# ATSAM4E16CB device description
Architecture: CORTEX-M4; Family: SAM4; Series: SAM4E
Registers are 32-bit, read-write, no defined reset value unless marked. A register's access mark holds for its fields unless they carry their own. Offsets are from the block's base; [hi:lo] are bit positions; {n}, {i} and the like mark numbered series.

## GPBR — General Purpose Backup Registers
Instances: GPBR 0x400E1890
{0x0+4i} SYS_GPBR{i} (i=0..19) — General Purpose Backup Register {i}
  [31:0] GPBR_VALUE — Value of GPBR x

## MATRIX — AHB Bus Matrix
Instances: MATRIX 0x400E0200
{0x0+4i} MATRIX_MCFG{i} (i=0..6) — Master Configuration Register {i}
  [2:0] ULBT — Undefined Length Burst Type
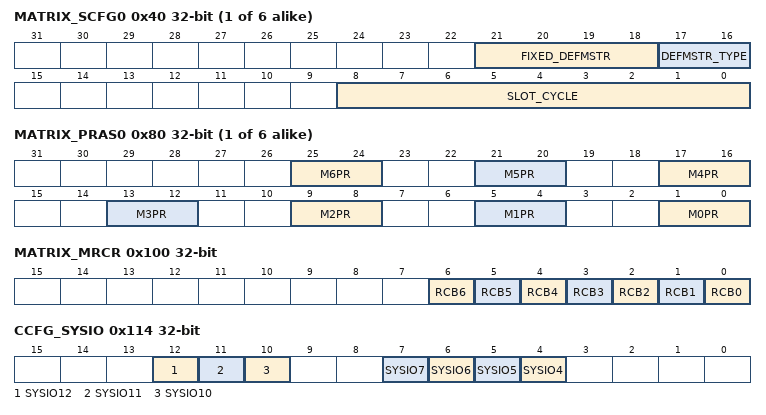
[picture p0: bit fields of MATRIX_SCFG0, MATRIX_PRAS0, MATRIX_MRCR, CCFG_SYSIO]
{0x40+4i} MATRIX_SCFG{i} (i=0..5) — Slave Configuration Register {i}
  [21:18] FIXED_DEFMSTR — Fixed Default Master
  [17:16] DEFMSTR_TYPE — Default Master Type
  [8:0] SLOT_CYCLE — Maximum Bus Grant Duration for Masters
{0x80+8i} MATRIX_PRAS{i} (i=0..5) — Priority Register A for Slave {i}
  [4n+1:4n] M{n}PR (n=0..6) — Master {n} Priority
0x100 MATRIX_MRCR — Master Remap Control Register
  [n] RCB{n} (n=0..6) — Remap Command Bit for Master {n}
0x114 CCFG_SYSIO — System I/O Configuration Register
  [12] SYSIO12 — PB12 or ERASE Assignment
  [11] SYSIO11 — PB11 or DDP Assignment
  [10] SYSIO10 — PB10 or DDM Assignment
  [7] SYSIO7 — PB7 or TCK/SWCLK Assignment
  [6] SYSIO6 — PB6 or TMS/SWDIO Assignment
  [5] SYSIO5 — PB5 or TDO/TRACESWO Assignment
  [4] SYSIO4 — PB4 or TDI Assignment
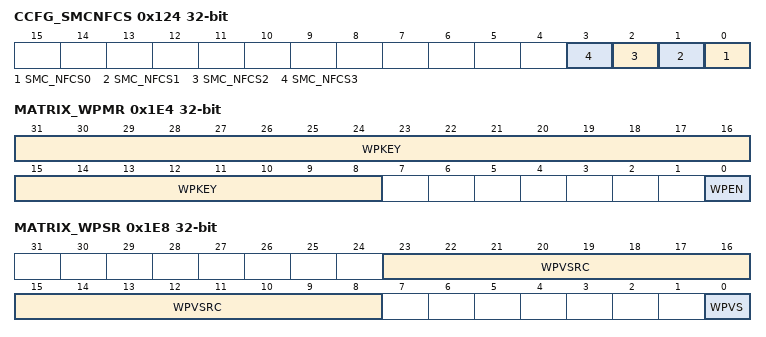
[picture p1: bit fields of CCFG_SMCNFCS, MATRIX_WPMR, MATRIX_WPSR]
0x124 CCFG_SMCNFCS — SMC NAND Flash Chip Select Configuration Register
  [n] SMC_NFCS{n} (n=0..3) — SMC NAND Flash Chip Select {n} Assignment
0x1E4 MATRIX_WPMR — Write Protect Mode Register
  [31:8] WPKEY — Write Protect KEY (Write-only)
    0x4D4154=PASSWD (Writing any other value in this field aborts the write operation of the WPEN bit.Always reads as 0.)
  [0] WPEN — Write Protect Enable
0x1E8 MATRIX_WPSR ro — Write Protect Status Register
  [23:8] WPVSRC — Write Protect Violation Source
  [0] WPVS — Write Protect Violation Status

## PDC — Peripheral DMA Controller
0x00 PERIPH_RPR — Receive Pointer Register
  [31:0] RXPTR
0x04 PERIPH_RCR — Receive Counter Register
  [15:0] RXCTR
0x08 PERIPH_TPR — Transmit Pointer Register
  [31:0] TXPTR — Transmit Counter Register
0x0C PERIPH_TCR — Transmit Counter Register
  [15:0] TXCTR
0x10 PERIPH_RNPR — Receive Next Pointer Register
  [31:0] RXNPTR — Receive Next Pointer
0x14 PERIPH_RNCR — Receive Next Counter Register
  [15:0] RXNCTR — Receive Next Counter
0x18 PERIPH_TNPR — Transmit Next Pointer Register
  [31:0] TXNPTR — Transmit Next Pointer
0x1C PERIPH_TNCR — Transmit Next Counter Register
  [15:0] TXNCTR — Transmit Counter Next
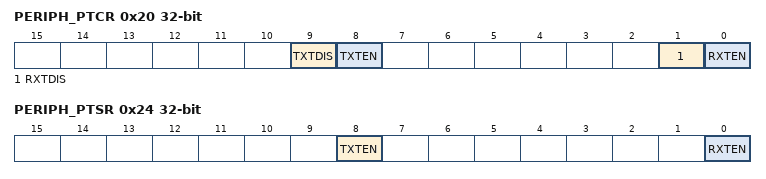
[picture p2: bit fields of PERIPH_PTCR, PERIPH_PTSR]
0x20 PERIPH_PTCR wo — Transfer Control Register
  [9] TXTDIS — Transmitter Transfer Disable
  [8] TXTEN — Transmitter Transfer Enable
  [1] RXTDIS — Receiver Transfer Disable
  [0] RXTEN — Receiver Transfer Enable
0x24 PERIPH_PTSR ro — Transfer Status Register
  [8] TXTEN — Transmitter Transfer Enable
  [0] RXTEN — Receiver Transfer Enable

## RSTC — Reset Controller
Instances: RSTC 0x400E1800
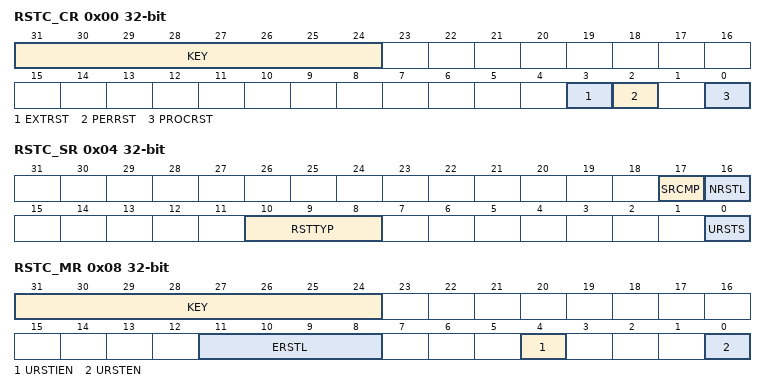
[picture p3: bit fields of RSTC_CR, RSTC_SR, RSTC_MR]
0x00 RSTC_CR wo — Control Register
  [31:24] KEY — System Reset Key
    165=PASSWD (Writing any other value in this field aborts the write operation.)
  [3] EXTRST — External Reset
  [2] PERRST — Peripheral Reset
  [0] PROCRST — Processor Reset
0x04 RSTC_SR ro — Status Register
  [17] SRCMP — Software Reset Command in Progress
  [16] NRSTL — NRST Pin Level
  [10:8] RSTTYP — Reset Type
    0=GENERAL_RST (First power-up reset); 1=BACKUP_RST (Return from Backup Mode); 2=WDT_RST (Watchdog fault occurred); 3=SOFT_RST (Processor reset required by the software); 4=USER_RST (NRST pin detected low)
  [0] URSTS — User Reset Status
0x08 RSTC_MR — Mode Register
  [31:24] KEY — Write Access Password
    165=PASSWD (Writing any other value in this field aborts the write operation.Always reads as 0.)
  [11:8] ERSTL — External Reset Length
  [4] URSTIEN — User Reset Interrupt Enable
  [0] URSTEN — User Reset Enable
